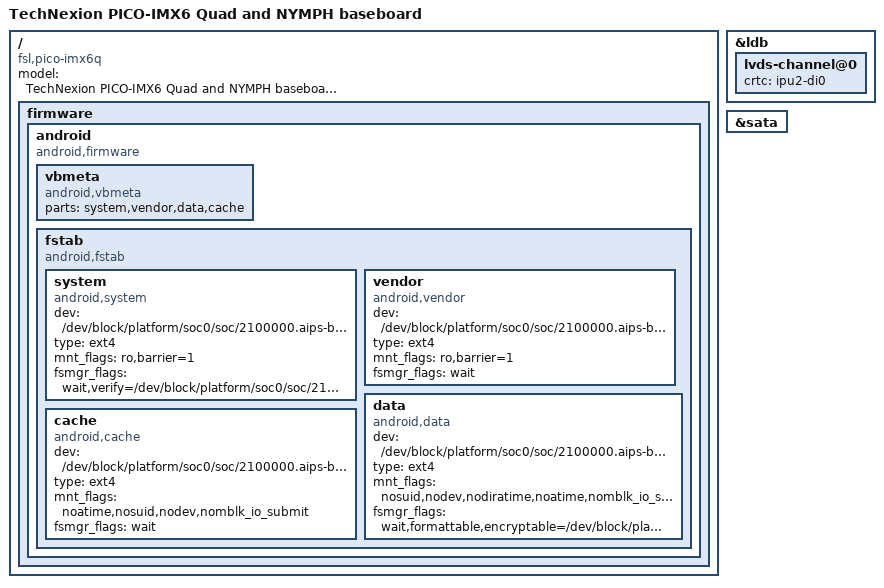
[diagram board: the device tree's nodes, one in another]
/*
 * Copyright 2016,2017,2018 Technexion Ltd.
 *
 * Author: Wig Cheng <wig.cheng@technexion.com>
 *         Richard Hu <richard.hu@technexion.com>
 *         Tapani Utriainen <tapani@technexion.com>
 *
 * This program is free software; you can redistribute it and/or modify
 * it under the terms of the GNU General Public License version 2 as
 * published by the Free Software Foundation.
 *
 */
/dts-v1/;

#include "imx6q.dtsi"
#include "imx6qdl-pico-lvds10.dtsi"
#include "baseboard_pico_nymph.dtsi"
/ {
	model = "TechNexion PICO-IMX6 Quad and NYMPH baseboard";
	compatible = "fsl,pico-imx6q", "fsl,imx6q";

	firmware {
		android {
			compatible = "android,firmware";
			vbmeta {
				compatible = "android,vbmeta";
				parts = "system,vendor,data,cache";
			};
			fstab {
				compatible = "android,fstab";
					system {
						compatible = "android,system";
						dev = "/dev/block/platform/soc0/soc/2100000.aips-bus/2198000.usdhc/by-name/system";
						type = "ext4";
						mnt_flags = "ro,barrier=1";
						fsmgr_flags = "wait,verify=/dev/block/platform/soc0/soc/2100000.aips-bus/2198000.usdhc/by-name/metadata";
					};
					vendor {
						compatible = "android,vendor";
						dev = "/dev/block/platform/soc0/soc/2100000.aips-bus/2198000.usdhc/by-name/vendor";
						type = "ext4";
						mnt_flags = "ro,barrier=1";
						fsmgr_flags = "wait";
					};
					data {
						compatible = "android,data";
						dev = "/dev/block/platform/soc0/soc/2100000.aips-bus/2198000.usdhc/by-name/userdata";
						type = "ext4";
						mnt_flags = "nosuid,nodev,nodiratime,noatime,nomblk_io_submit,noauto_da_alloc,errors=panic";
						fsmgr_flags = "wait,formattable,encryptable=/dev/block/platform/soc0/soc/2100000.aips-bus/2198000.usdhc/by-name/datafooter,quota";
					};
					cache {
						compatible = "android,cache";
						dev = "/dev/block/platform/soc0/soc/2100000.aips-bus/2198000.usdhc/by-name/cache";
						type = "ext4";
						mnt_flags = "noatime,nosuid,nodev,nomblk_io_submit";
						fsmgr_flags = "wait";
					};
			};
		};
	};

};

&ldb {
	lvds-channel@0 {
		crtc = "ipu2-di0";
	};
};

&sata {
	status = "okay";
};

